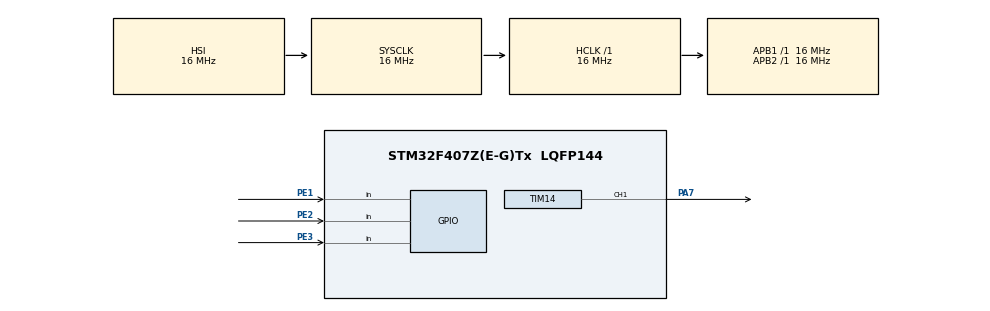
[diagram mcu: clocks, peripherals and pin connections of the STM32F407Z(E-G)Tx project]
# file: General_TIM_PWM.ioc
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Mcu.Family=STM32F4
Mcu.Name=STM32F407Z(E-G)Tx
Mcu.Package=LQFP144
NVIC.PriorityGroup=NVIC_PRIORITYGROUP_4
NVIC.TIM8_TRG_COM_TIM14_IRQn=true\:0\:0\:false\:false\:true\:true\:true\:true
PA7.Signal=S_TIM14_CH1
PE1.Signal=GPIO_Input
PE2.Signal=GPIO_Input
PE3.Signal=GPIO_Input
ProjectManager.HeapSize=0x200
ProjectManager.StackSize=0x400
ProjectManager.TargetToolchain=MDK-ARM V5.32
RCC.48MHZClocksFreq_Value=48000000
RCC.AHBFreq_Value=16000000
RCC.APB1Freq_Value=16000000
RCC.APB1TimFreq_Value=16000000
RCC.APB2Freq_Value=16000000
RCC.APB2TimCLKDivider=1
RCC.APB2TimFreq_Value=16000000
RCC.CortexFreq_Value=16000000
RCC.HCLKFreq_Value=16000000
RCC.HSE_VALUE=25000000
RCC.HSI_VALUE=16000000
RCC.LSE_VALUE=32768
RCC.SYSCLKFreq_VALUE=16000000
RCC.VCOOutputFreq_Value=192000000
SH.S_TIM14_CH1.0=TIM14_CH1,PWM Generation1 CH1
TIM14.Channel=TIM_CHANNEL_1
TIM14.Period=19
TIM14.Prescaler=15999
VP_TIM14_VS_ClockSourceINT.Mode=Enable_Timer
board=custom

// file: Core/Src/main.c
/* USER CODE BEGIN Header */
/**
  ******************************************************************************
  * @file           : main.c
  * @brief          : Main program body
  ******************************************************************************
  * @attention
  *
  * Copyright (c) 2025 STMicroelectronics.
  * All rights reserved.
  *
  * This software is licensed under terms that can be found in the LICENSE file
  * in the root directory of this software component.
  * If no LICENSE file comes with this software, it is provided AS-IS.
  *
  ******************************************************************************
  */
/* USER CODE END Header */
#include "main.h"
#include "tim.h"
#include "gpio.h"

void SystemClock_Config(void);

/* USER CODE BEGIN 0 */
int flag = 0;
/* USER CODE END 0 */

int main(void)
{

  /* MCU Configuration--------------------------------------------------------*/

  /* Reset of all peripherals, Initializes the Flash interface and the Systick. */
  HAL_Init();

  /* Configure the system clock */
  SystemClock_Config();

  /* Initialize all configured peripherals */
  MX_GPIO_Init();
  MX_TIM14_Init();
  /* USER CODE BEGIN 2 */
	HAL_TIM_Base_Start_IT(&htim14);
	HAL_TIM_PWM_Start(&htim14, TIM_CHANNEL_1);
	__HAL_TIM_SetCompare(&htim14, TIM_CHANNEL_1, 5);
  /* USER CODE END 2 */

  /* Infinite loop */
  /* USER CODE BEGIN WHILE */
  while (1)
  {
		if(HAL_GPIO_ReadPin(GPIOE, GPIO_PIN_1)==RESET) flag=1;
		else if(HAL_GPIO_ReadPin(GPIOE, GPIO_PIN_2)==RESET) flag=2;
		else if(HAL_GPIO_ReadPin(GPIOE, GPIO_PIN_3)==RESET) flag=3;
		if(flag == 1)
		{
			__HAL_TIM_SetCompare(&htim14, TIM_CHANNEL_1, 5);
		}
		else if(flag == 2)
		{
			__HAL_TIM_SetCompare(&htim14, TIM_CHANNEL_1, 10);
		}
		else if(flag == 3)
		{
			__HAL_TIM_SetCompare(&htim14, TIM_CHANNEL_1, 15);
		}
    /* USER CODE END WHILE */

  }
}

void SystemClock_Config(void)
{
  RCC_OscInitTypeDef RCC_OscInitStruct = {0};
  RCC_ClkInitTypeDef RCC_ClkInitStruct = {0};

  /** Configure the main internal regulator output voltage
  */
  __HAL_RCC_PWR_CLK_ENABLE();
  __HAL_PWR_VOLTAGESCALING_CONFIG(PWR_REGULATOR_VOLTAGE_SCALE1);

  /** Initializes the RCC Oscillators according to the specified parameters
  * in the RCC_OscInitTypeDef structure.
  */
  RCC_OscInitStruct.OscillatorType = RCC_OSCILLATORTYPE_HSI;
  RCC_OscInitStruct.HSIState = RCC_HSI_ON;
  RCC_OscInitStruct.HSICalibrationValue = RCC_HSICALIBRATION_DEFAULT;
  RCC_OscInitStruct.PLL.PLLState = RCC_PLL_NONE;
  if (HAL_RCC_OscConfig(&RCC_OscInitStruct) != HAL_OK)
  {
    Error_Handler();
  }

  /** Initializes the CPU, AHB and APB buses clocks
  */
  RCC_ClkInitStruct.ClockType = RCC_CLOCKTYPE_HCLK|RCC_CLOCKTYPE_SYSCLK
                              |RCC_CLOCKTYPE_PCLK1|RCC_CLOCKTYPE_PCLK2;
  RCC_ClkInitStruct.SYSCLKSource = RCC_SYSCLKSOURCE_HSI;
  RCC_ClkInitStruct.AHBCLKDivider = RCC_SYSCLK_DIV1;
  RCC_ClkInitStruct.APB1CLKDivider = RCC_HCLK_DIV1;
  RCC_ClkInitStruct.APB2CLKDivider = RCC_HCLK_DIV1;

  if (HAL_RCC_ClockConfig(&RCC_ClkInitStruct, FLASH_LATENCY_0) != HAL_OK)
  {
    Error_Handler();
  }
}

void Error_Handler(void)
{
  __disable_irq();
  while (1)
  {
  }
}
